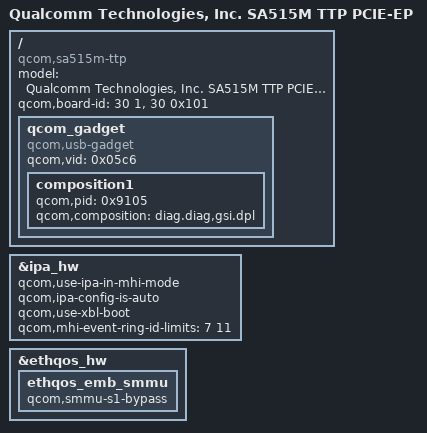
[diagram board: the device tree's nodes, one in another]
/* Copyright (c) 2019-2020, The Linux Foundation. All rights reserved.
 *
 * This program is free software; you can redistribute it and/or modify
 * it under the terms of the GNU General Public License version 2 and
 * only version 2 as published by the Free Software Foundation.
 *
 * This program is distributed in the hope that it will be useful,
 * but WITHOUT ANY WARRANTY; without even the implied warranty of
 * MERCHANTABILITY or FITNESS FOR A PARTICULAR PURPOSE.  See the
 * GNU General Public License for more details.
 */

/dts-v1/;

#include "sa515m-v2-ttp.dtsi"

/ {
	model = "Qualcomm Technologies, Inc. SA515M TTP PCIE-EP";
	compatible = "qcom,sa515m-ttp",
		"qcom,sdxprairie","qcom,ttp";
	qcom,board-id = <30 1> , <30 0x101>;

	/delete-node/ qcom_gadget;
	qcom_gadget {
		compatible = "qcom,usb-gadget";
		qcom,vid = <0x05c6>;

		composition1 {
			qcom,pid = <0x9105>;
			qcom,composition = "diag.diag,gsi.dpl";
		};
	};
};

&ipa_hw {
	qcom,use-ipa-in-mhi-mode;
	qcom,ipa-config-is-auto;
	qcom,use-xbl-boot;
	qcom,mhi-event-ring-id-limits = <7 11>; /* start and end */
};

&ethqos_hw {
	ethqos_emb_smmu: ethqos_emb_smmu {
		qcom,smmu-s1-bypass;
	};
};
